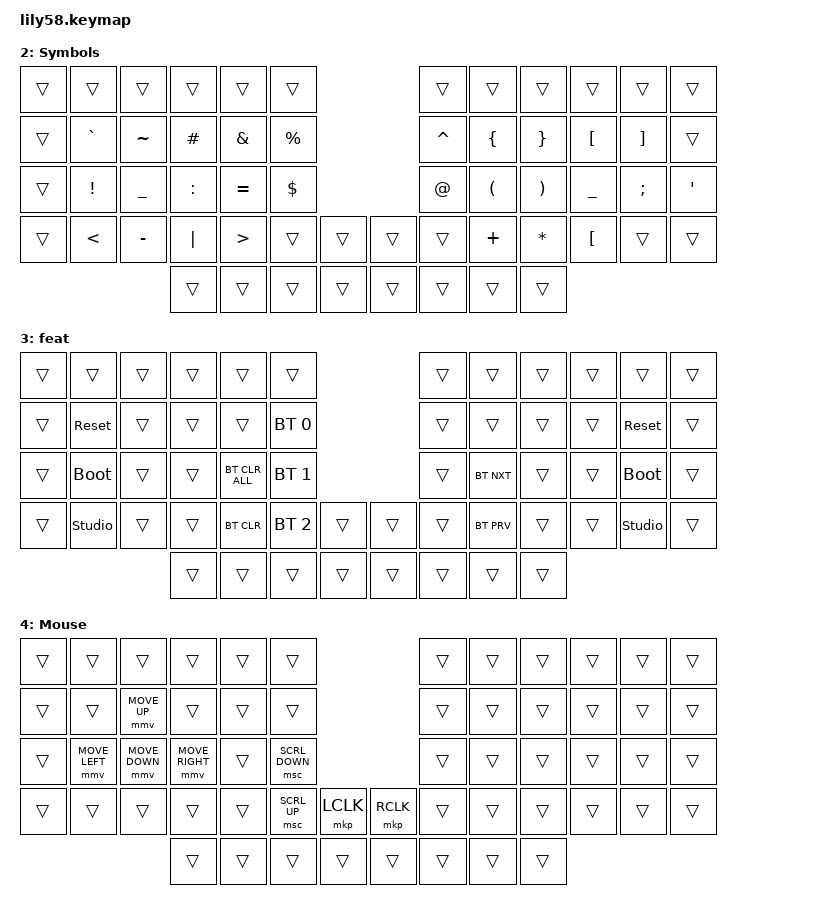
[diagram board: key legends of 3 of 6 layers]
/*
 * Copyright (c) 2020 The ZMK Contributors
 *
 * SPDX-License-Identifier: MIT
 */

#include <behaviors.dtsi>
#include <dt-bindings/zmk/bt.h>
#include <dt-bindings/zmk/keys.h>
#include <dt-bindings/zmk/pointing.h>

#define default_layer 0
#define lower_layer 1
#define raise_layer 2
#define adjust_layer 3
#define extra 4
#define gaming 5

// Home row mods macro
#define HRML(k1,k2,k3,k4) &ht LGUI k1  &ht LALT k2  &ht LCTRL k3  &ht LSHFT k4
#define HRMR(k1,k2,k3,k4) &ht RSHFT k1  &ht RCTRL k2  &ht RALT k3  &ht RGUI k4

/ {
    behaviors {
        ht: hold_tap {
            compatible = "zmk,behavior-hold-tap";
            #binding-cells = <2>;
            flavor = "tap-preferred";
            tapping-term-ms = <180>;
            quick-tap-ms = <140>;
            require-prior-idle-ms = <0>;
            retro-tap;
            bindings = <&kp>, <&kp>;
        };
    };

    keymap {
        compatible = "zmk,keymap";

        default_layer {
            display-name = "Base";
            bindings = <
&tog 5   &kp N1  &kp N2  &kp N3      &kp N4          &kp N5                                   &kp N6     &kp N7    &kp N8      &kp N9   &kp N0            &kp MINUS
&kp DEL    &kp Q   &kp W   &kp E       &kp R           &kp T                                    &kp Y      &kp U     &kp I       &kp O    &kp P             &kp BACKSLASH
&kp ESC    HRML(A,        S,         D,         F)     &kp G                                    &kp H      HRMR(J,        K,         L,        SQT)         &kp SEMI
&kp GRAVE  &kp Z   &kp X   &kp C       &kp V           &kp B          &kp LBKT     &kp RBKT     &kp N      &kp M     &kp COMMA   &kp DOT  &kp FSLH          &tog 4
                           &caps_word  &lt 3 LEFT_ALT  &lt 1 TAB      &kp BACKSPACE &kp SPACE   &lt 2 ENTER &kp BSPC  &caps_word
            >;
        };

        nav_layer {
            display-name = "Nav";
            bindings = <
&kp F12  &kp C_BRI_DN  &kp C_BRI_UP  &kp C_MUTE  &kp C_VOL_DN  &kp C_VOL_UP                    &trans    &trans         &trans       &trans           &trans    &trans
&trans   &kp F1        &kp F2        &kp F3      &kp F4        &kp F5                          &kp F6    &kp F7         &kp F8       &kp F9           &kp F10   &kp F11
&trans   HRML(&trans,  &trans,   &trans,    &trans)            &trans                          &kp LEFT  &kp DOWN       &kp UP       &kp RIGHT_ARROW  &kp RPAR  &kp TILDE
&trans   &trans        &trans        &trans      &trans        &trans        &trans    &trans  &kp HOME  &kp PAGE_DOWN  &kp PAGE_UP  &kp END          &kp RBRC  &kp PIPE
                                     &trans      &trans        &trans        &trans    &trans  &trans    &trans         &trans
            >;
        };

        sym_layer {
            display-name = "Symbols";
            bindings = <
&trans  &trans           &trans          &trans     &trans            &trans                         &trans       &trans                &trans                 &trans            &trans             &trans
&trans  &kp GRAVE        &kp TILDE       &kp HASH   &kp AMPERSAND     &kp PERCENT                    &kp CARET    &kp LEFT_BRACE        &kp RIGHT_BRACE        &kp LEFT_BRACKET  &kp RIGHT_BRACKET  &trans
&trans  &kp EXCLAMATION  &kp UNDERSCORE  &kp COLON  &kp EQUAL         &kp DOLLAR                     &kp AT_SIGN  &kp LEFT_PARENTHESIS  &kp RIGHT_PARENTHESIS  &kp UNDERSCORE    &kp SEMICOLON      &kp SINGLE_QUOTE
&trans  &kp LESS_THAN    &kp MINUS       &kp PIPE   &kp GREATER_THAN  &trans       &trans    &trans  &trans       &kp PLUS              &kp ASTERISK           &kp LBKT          &trans             &trans
                                         &trans     &trans            &trans       &trans    &trans  &trans       &trans                &trans
            >;
        };

        feat_layer {
            display-name = "feat";
            bindings = <
&trans  &trans          &trans  &trans  &trans          &trans                          &trans  &trans      &trans  &trans  &trans          &trans
&trans  &sys_reset      &trans  &trans  &trans          &bt BT_SEL 0                    &trans  &trans      &trans  &trans  &sys_reset      &trans
&trans  &bootloader     &trans  &trans  &bt BT_CLR_ALL  &bt BT_SEL 1                    &trans  &bt BT_NXT  &trans  &trans  &bootloader     &trans
&trans  &studio_unlock  &trans  &trans  &bt BT_CLR      &bt BT_SEL 2  &trans    &trans  &trans  &bt BT_PRV  &trans  &trans  &studio_unlock  &trans
                                &trans  &trans          &trans        &trans    &trans  &trans  &trans      &trans
            >;
        };

        extra {
            display-name = "Mouse";
            bindings = <
&trans  &trans          &trans          &trans           &trans  &trans                                  &trans  &trans  &trans  &trans  &trans  &trans
&trans  &trans          &mmv MOVE_UP    &trans           &trans  &trans                                  &trans  &trans  &trans  &trans  &trans  &trans
&trans  &mmv MOVE_LEFT  &mmv MOVE_DOWN  &mmv MOVE_RIGHT  &trans  &msc SCRL_DOWN                          &trans  &trans  &trans  &trans  &trans  &trans
&trans  &trans          &trans          &trans           &trans  &msc SCRL_UP    &mkp LCLK    &mkp RCLK  &trans  &trans  &trans  &trans  &trans  &trans
                                        &trans           &trans  &trans          &trans       &trans     &trans  &trans  &trans
            >;
        };

        gaming {
            display-name = "Gaming";
            bindings = <
&trans    &kp N1  &kp N2  &kp N3      &kp N4          &kp N5                                   &kp N6     &kp N7    &kp N8      &kp N9   &kp N0            &kp MINUS
&kp ESC    &kp Q   &kp W   &kp E       &kp R           &kp T                                    &kp Y      &kp U     &kp I       &kp O    &kp P             &kp BACKSLASH
&kp LSHFT    &kp A   &kp S   &kp D       &kp F   &kp G                                    &kp H      HRMR(J,        K,         L,        SQT)         &kp SEMI
&kp LCTRL  &kp Z   &kp X   &kp C       &kp V           &kp B          &kp LBKT     &kp RBKT     &kp N      &kp M     &kp COMMA   &kp DOT  &kp FSLH          &trans
                           &kp LGUI  &kp LEFT_ALT  &kp TAB      &kp SPACE &kp SPACE   &lt 2 ENTER &kp BSPC  &caps_word
            >;
        };
    };
};
